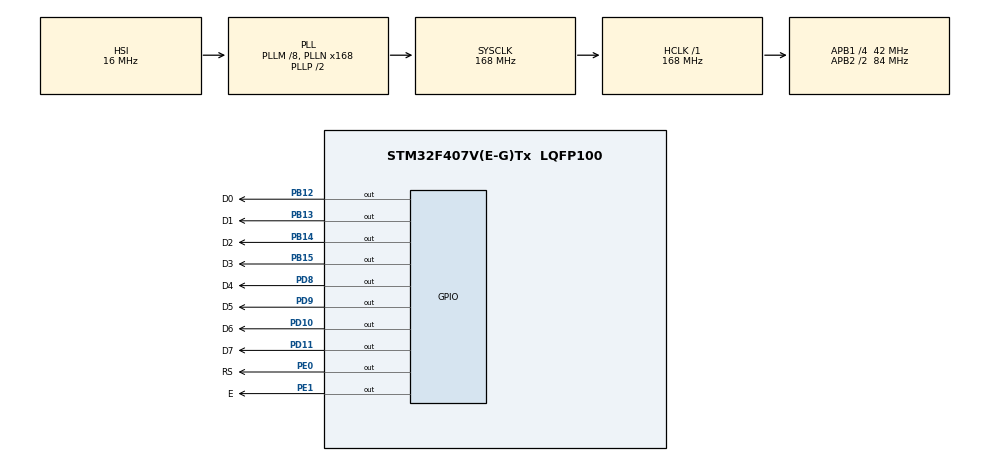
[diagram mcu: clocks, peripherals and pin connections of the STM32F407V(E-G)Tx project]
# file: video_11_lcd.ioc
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Mcu.Family=STM32F4
Mcu.Name=STM32F407V(E-G)Tx
Mcu.Package=LQFP100
NVIC.PriorityGroup=NVIC_PRIORITYGROUP_4
PA13.Mode=Serial_Wire
PA13.Signal=SYS_JTMS-SWDIO
PA14.Mode=Serial_Wire
PA14.Signal=SYS_JTCK-SWCLK
PB12.GPIO_Label=D0
PB12.Signal=GPIO_Output
PB13.GPIO_Label=D1
PB13.Signal=GPIO_Output
PB14.GPIO_Label=D2
PB14.Signal=GPIO_Output
PB15.GPIO_Label=D3
PB15.Signal=GPIO_Output
PD10.GPIO_Label=D6
PD10.Signal=GPIO_Output
PD11.GPIO_Label=D7
PD11.Signal=GPIO_Output
PD8.GPIO_Label=D4
PD8.Signal=GPIO_Output
PD9.GPIO_Label=D5
PD9.Signal=GPIO_Output
PE0.GPIO_Label=RS
PE0.Signal=GPIO_Output
PE1.GPIO_Label=E
PE1.Signal=GPIO_Output
ProjectManager.HeapSize=0x200
ProjectManager.StackSize=0x400
ProjectManager.TargetToolchain=MDK-ARM V5
RCC.48MHZClocksFreq_Value=84000000
RCC.AHBFreq_Value=168000000
RCC.APB1CLKDivider=RCC_HCLK_DIV4
RCC.APB1Freq_Value=42000000
RCC.APB1TimFreq_Value=84000000
RCC.APB2CLKDivider=RCC_HCLK_DIV2
RCC.APB2Freq_Value=84000000
RCC.APB2TimFreq_Value=168000000
RCC.CortexFreq_Value=168000000
RCC.HCLKFreq_Value=168000000
RCC.HSE_VALUE=25000000
RCC.HSI_VALUE=16000000
RCC.LSE_VALUE=32768
RCC.PLLM=8
RCC.PLLN=168
RCC.SYSCLKFreq_VALUE=168000000
RCC.SYSCLKSource=RCC_SYSCLKSOURCE_PLLCLK
RCC.VCOOutputFreq_Value=336000000
board=video_11_lcd

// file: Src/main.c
/**
  ******************************************************************************
  * File Name          : main.c
  * Description        : Main program body
  ******************************************************************************
  ** This notice applies to any and all portions of this file
  * that are not between comment pairs USER CODE BEGIN and
  * USER CODE END. Other portions of this file, whether
  * inserted by the user or by software development tools
  * are owned by their respective copyright owners.
  *
  * COPYRIGHT(c) 2018 STMicroelectronics
  *
  * Redistribution and use in source and binary forms, with or without modification,
  * are permitted provided that the following conditions are met:
  *   1. Redistributions of source code must retain the above copyright notice,
  *      this list of conditions and the following disclaimer.
  *   2. Redistributions in binary form must reproduce the above copyright notice,
  *      this list of conditions and the following disclaimer in the documentation
  *      and/or other materials provided with the distribution.
  *   3. Neither the name of STMicroelectronics nor the names of its contributors
  *      may be used to endorse or promote products derived from this software
  *      without specific prior written permission.
  *
  * THIS SOFTWARE IS PROVIDED BY THE COPYRIGHT HOLDERS AND CONTRIBUTORS "AS IS"
  * AND ANY EXPRESS OR IMPLIED WARRANTIES, INCLUDING, BUT NOT LIMITED TO, THE
  * IMPLIED WARRANTIES OF MERCHANTABILITY AND FITNESS FOR A PARTICULAR PURPOSE ARE
  * DISCLAIMED. IN NO EVENT SHALL THE COPYRIGHT HOLDER OR CONTRIBUTORS BE LIABLE
  * FOR ANY DIRECT, INDIRECT, INCIDENTAL, SPECIAL, EXEMPLARY, OR CONSEQUENTIAL
  * DAMAGES (INCLUDING, BUT NOT LIMITED TO, PROCUREMENT OF SUBSTITUTE GOODS OR
  * SERVICES; LOSS OF USE, DATA, OR PROFITS; OR BUSINESS INTERRUPTION) HOWEVER
  * CAUSED AND ON ANY THEORY OF LIABILITY, WHETHER IN CONTRACT, STRICT LIABILITY,
  * OR TORT (INCLUDING NEGLIGENCE OR OTHERWISE) ARISING IN ANY WAY OUT OF THE USE
  * OF THIS SOFTWARE, EVEN IF ADVISED OF THE POSSIBILITY OF SUCH DAMAGE.
  *
  ******************************************************************************
  */
#include "main.h"
#include "stm32f4xx_hal.h"

/* USER CODE BEGIN Includes */
#include "STM_MY_LCD16X2.h" // lcd library'si
/* USER CODE END Includes */

/* USER CODE BEGIN PV */
/* Private variables ---------------------------------------------------------*/

/* USER CODE END PV */

void SystemClock_Config(void);
static void MX_GPIO_Init(void);

/* USER CODE BEGIN PFP */
/* Private function prototypes -----------------------------------------------*/

/* USER CODE END PFP */

int main(void)
{

  /* MCU Configuration----------------------------------------------------------*/

  /* Reset of all peripherals, Initializes the Flash interface and the Systick. */
  HAL_Init();

  /* Configure the system clock */
  SystemClock_Config();

  /* Initialize all configured peripherals */
  MX_GPIO_Init();

  /* USER CODE BEGIN 2 */
	// 8 pini kullanacagimiz için begin8biti seçtik
 //   LCD1602_Begin8BIT(RS_GPIO_Port,RS_Pin,E_Pin,D0_GPIO_Port,D0_Pin,D1_Pin,D2_Pin,D3_Pin,D4_GPIO_Port,D4_Pin,D5_Pin,D6_Pin,D7_Pin);

// 4 bit kullanimi:
LCD1602_Begin4BIT(RS_GPIO_Port,RS_Pin,E_Pin,D4_GPIO_Port,D4_Pin,D5_Pin,D6_Pin,D7_Pin);
// buda çalisiyor....

// isim verdik rs,e vs filan onlari yazdik anlamak için lcd1602_begin8bit e bakilmali.
  // .h dosyasinda ki fonksiyonlarda ne yazilmasi gerekiyor onlar var.
	// main.h da hangi pinin ne oldugu yaziyor constant tanimli
//  LCD1602_clear();
//	LCD1602_print("Hello wolrd");
//	LCD1602_2ndLine();
//	LCD1602_print("2. satirdayiz");
//	HAL_Delay(1000);

 /* USER CODE END 2 */

  /* Infinite loop */
  while (1)
  {
	LCD1602_print("Hello world");
	LCD1602_2ndLine();
	LCD1602_print("2. satirdayiz");
	HAL_Delay(1000);
	LCD1602_clear();
	LCD1602_PrintInt(1234);
	HAL_Delay(1000);
  LCD1602_2ndLine();
  LCD1602_PrintFloat(14.5687,3);
	HAL_Delay(1000);
	LCD1602_clear();
  }

}

/** System Clock Configuration
*/
void SystemClock_Config(void)
{

  RCC_OscInitTypeDef RCC_OscInitStruct;
  RCC_ClkInitTypeDef RCC_ClkInitStruct;

    /**Configure the main internal regulator output voltage
    */
  __HAL_RCC_PWR_CLK_ENABLE();

  __HAL_PWR_VOLTAGESCALING_CONFIG(PWR_REGULATOR_VOLTAGE_SCALE1);

    /**Initializes the CPU, AHB and APB busses clocks
    */
  RCC_OscInitStruct.OscillatorType = RCC_OSCILLATORTYPE_HSI;
  RCC_OscInitStruct.HSIState = RCC_HSI_ON;
  RCC_OscInitStruct.HSICalibrationValue = 16;
  RCC_OscInitStruct.PLL.PLLState = RCC_PLL_ON;
  RCC_OscInitStruct.PLL.PLLSource = RCC_PLLSOURCE_HSI;
  RCC_OscInitStruct.PLL.PLLM = 8;
  RCC_OscInitStruct.PLL.PLLN = 168;
  RCC_OscInitStruct.PLL.PLLP = RCC_PLLP_DIV2;
  RCC_OscInitStruct.PLL.PLLQ = 4;
  if (HAL_RCC_OscConfig(&RCC_OscInitStruct) != HAL_OK)
  {
    _Error_Handler(__FILE__, __LINE__);
  }

    /**Initializes the CPU, AHB and APB busses clocks
    */
  RCC_ClkInitStruct.ClockType = RCC_CLOCKTYPE_HCLK|RCC_CLOCKTYPE_SYSCLK
                              |RCC_CLOCKTYPE_PCLK1|RCC_CLOCKTYPE_PCLK2;
  RCC_ClkInitStruct.SYSCLKSource = RCC_SYSCLKSOURCE_PLLCLK;
  RCC_ClkInitStruct.AHBCLKDivider = RCC_SYSCLK_DIV1;
  RCC_ClkInitStruct.APB1CLKDivider = RCC_HCLK_DIV4;
  RCC_ClkInitStruct.APB2CLKDivider = RCC_HCLK_DIV2;

  if (HAL_RCC_ClockConfig(&RCC_ClkInitStruct, FLASH_LATENCY_5) != HAL_OK)
  {
    _Error_Handler(__FILE__, __LINE__);
  }

    /**Configure the Systick interrupt time
    */
  HAL_SYSTICK_Config(HAL_RCC_GetHCLKFreq()/1000);

    /**Configure the Systick
    */
  HAL_SYSTICK_CLKSourceConfig(SYSTICK_CLKSOURCE_HCLK);

  /* SysTick_IRQn interrupt configuration */
  HAL_NVIC_SetPriority(SysTick_IRQn, 0, 0);
}

/** Configure pins as
        * Analog
        * Input
        * Output
        * EVENT_OUT
        * EXTI
*/
static void MX_GPIO_Init(void)
{

  GPIO_InitTypeDef GPIO_InitStruct;

  /* GPIO Ports Clock Enable */
  __HAL_RCC_GPIOB_CLK_ENABLE();
  __HAL_RCC_GPIOD_CLK_ENABLE();
  __HAL_RCC_GPIOA_CLK_ENABLE();
  __HAL_RCC_GPIOE_CLK_ENABLE();

  /*Configure GPIO pin Output Level */
  HAL_GPIO_WritePin(GPIOB, D0_Pin|D1_Pin|D2_Pin|D3_Pin, GPIO_PIN_RESET);

  /*Configure GPIO pin Output Level */
  HAL_GPIO_WritePin(GPIOD, D4_Pin|D5_Pin|D6_Pin|D7_Pin, GPIO_PIN_RESET);

  /*Configure GPIO pin Output Level */
  HAL_GPIO_WritePin(GPIOE, RS_Pin|E_Pin, GPIO_PIN_RESET);

  /*Configure GPIO pins : D0_Pin D1_Pin D2_Pin D3_Pin */
  GPIO_InitStruct.Pin = D0_Pin|D1_Pin|D2_Pin|D3_Pin;
  GPIO_InitStruct.Mode = GPIO_MODE_OUTPUT_PP;
  GPIO_InitStruct.Pull = GPIO_NOPULL;
  GPIO_InitStruct.Speed = GPIO_SPEED_FREQ_LOW;
  HAL_GPIO_Init(GPIOB, &GPIO_InitStruct);

  /*Configure GPIO pins : D4_Pin D5_Pin D6_Pin D7_Pin */
  GPIO_InitStruct.Pin = D4_Pin|D5_Pin|D6_Pin|D7_Pin;
  GPIO_InitStruct.Mode = GPIO_MODE_OUTPUT_PP;
  GPIO_InitStruct.Pull = GPIO_NOPULL;
  GPIO_InitStruct.Speed = GPIO_SPEED_FREQ_LOW;
  HAL_GPIO_Init(GPIOD, &GPIO_InitStruct);

  /*Configure GPIO pins : RS_Pin E_Pin */
  GPIO_InitStruct.Pin = RS_Pin|E_Pin;
  GPIO_InitStruct.Mode = GPIO_MODE_OUTPUT_PP;
  GPIO_InitStruct.Pull = GPIO_NOPULL;
  GPIO_InitStruct.Speed = GPIO_SPEED_FREQ_LOW;
  HAL_GPIO_Init(GPIOE, &GPIO_InitStruct);

}

void _Error_Handler(char * file, int line)
{
  while(1)
  {
  }
}

/************************ (C) COPYRIGHT STMicroelectronics *****END OF FILE****/
